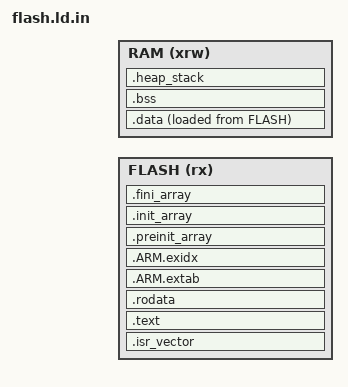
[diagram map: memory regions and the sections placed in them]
ENTRY(Reset_Handler)

MEMORY
{
    FLASH (rx)  : ORIGIN = @FLY_FLASH_ADDRESS@, LENGTH = @FLY_STM32_FLASH_SIZE@
    RAM   (xrw) : ORIGIN = @FLY_STM32_RAM_ADDRESS@, LENGTH = @FLY_STM32_RAM_SIZE@
}

_estack = ORIGIN(RAM) + LENGTH(RAM);

PHDRS
{
    flash PT_LOAD FLAGS(5);
    ram PT_LOAD FLAGS(6);
}

SECTIONS
{
    .isr_vector :
    {
        KEEP(*(.isr_vector))
    } > FLASH :flash

    .text :
    {
        *(.text .text.* .glue_7 .glue_7t)
        KEEP(*(.init))
        KEEP(*(.fini))
    } > FLASH

    .rodata :
    {
        *(.rodata .rodata.*)
    } > FLASH

    .ARM.extab :
    {
        *(.ARM.extab* .gnu.linkonce.armextab.*)
    } > FLASH

    .ARM.exidx :
    {
        __exidx_start = .;
        *(.ARM.exidx* .gnu.linkonce.armexidx.*)
        __exidx_end = .;
    } > FLASH

    .preinit_array : ALIGN(4)
    {
        PROVIDE_HIDDEN(__preinit_array_start = .);
        KEEP(*(.preinit_array))
        PROVIDE_HIDDEN(__preinit_array_end = .);
    } > FLASH

    .init_array : ALIGN(4)
    {
        PROVIDE_HIDDEN(__init_array_start = .);
        KEEP(*(SORT_BY_INIT_PRIORITY(.init_array.*)))
        KEEP(*(.init_array))
        PROVIDE_HIDDEN(__init_array_end = .);
    } > FLASH

    .fini_array : ALIGN(4)
    {
        PROVIDE_HIDDEN(__fini_array_start = .);
        KEEP(*(SORT_BY_INIT_PRIORITY(.fini_array.*)))
        KEEP(*(.fini_array))
        PROVIDE_HIDDEN(__fini_array_end = .);
    } > FLASH

    _sidata = LOADADDR(.data);
    .data : ALIGN(4)
    {
        _sdata = .;
        *(.data .data.*)
        . = ALIGN(4);
        _edata = .;
    } > RAM AT > FLASH :ram

    .bss (NOLOAD) : ALIGN(4)
    {
        _sbss = .;
        *(.bss .bss.* COMMON)
        . = ALIGN(4);
        _ebss = .;
    } > RAM :ram

    .heap_stack (NOLOAD) : ALIGN(8)
    {
        PROVIDE(end = .);
        PROVIDE(_end = .);
        . += 0x400;
    } > RAM :ram
}
